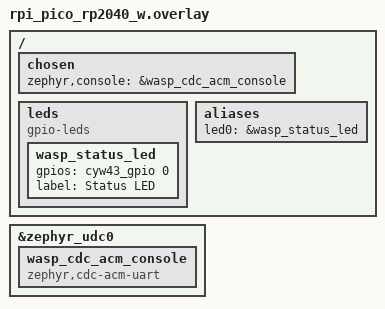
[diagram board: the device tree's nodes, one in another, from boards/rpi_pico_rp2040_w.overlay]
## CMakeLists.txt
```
cmake_minimum_required(VERSION 3.20.0)

# WAMR's zephyr module declares cmake-ext/kconfig-ext but ships no glue;
# supply it from app/modules/wamr (must be set before find_package(Zephyr)).
set(ZEPHYR_WASM_MICRO_RUNTIME_CMAKE_DIR ${CMAKE_CURRENT_SOURCE_DIR}/modules/wamr)
set(ZEPHYR_WASM_MICRO_RUNTIME_KCONFIG ${CMAKE_CURRENT_SOURCE_DIR}/modules/wamr/Kconfig)

# Local WiFi credentials (gitignored; copy wifi_credentials.conf.example).
# Merged automatically so build commands stay the same on every board.
if(EXISTS ${CMAKE_CURRENT_SOURCE_DIR}/wifi_credentials.conf)
  list(APPEND EXTRA_CONF_FILE ${CMAKE_CURRENT_SOURCE_DIR}/wifi_credentials.conf)
endif()

# Out-of-tree board definitions live at the repo root: boards/wasp/wasp_node.
# Both roots have to be set before find_package(Zephyr); DTS_ROOT is what
# makes dts/bindings/vendor-prefixes.txt visible so "wasp,..." compatibles
# are not flagged as an unknown vendor.
list(APPEND BOARD_ROOT ${CMAKE_CURRENT_SOURCE_DIR}/..)
list(APPEND DTS_ROOT ${CMAKE_CURRENT_SOURCE_DIR}/..)

find_package(Zephyr REQUIRED HINTS $ENV{ZEPHYR_BASE})
project(wasp LANGUAGES C)

target_sources(app PRIVATE
  src/main.c
  src/led.c
  src/net/netup.c
  # ROM USB bootloader entry; compiles to a pair of stubs where the SoC
  # has none.
  src/boot_dfu.c
  # Self-guards on the eth_switch devicetree node, so it compiles to nothing
  # on boards without a KSZ8794 (the Nucleos, the Picos).
  src/net/ksz8794.c
  # Likewise guards on the psram node.
  src/mem/psram.c
)

# Worker role: WAMR runtime, agent/executor threads, listening socket.
if(CONFIG_WASP_WORKER)
  target_sources(app PRIVATE
    src/rpc.c
    src/net/net_thread.c
    src/net/announce.c
    src/agent/agent_thread.c
    src/wamr/wamr_runtime.c
    src/wamr/native_remote.c
  )
endif()

target_include_directories(app PRIVATE src)

# Peer (job-owner) role: the libwasp core compiled into the firmware.
if(CONFIG_WASP_PEER)
  target_sources(app PRIVATE
    ../libwasp/src/core.c
    ../libwasp/src/host.c
    ../libwasp/src/discover.c
    ../libwasp/src/port_zephyr.c
    src/peer/peer_api.c
  )
  target_include_directories(app PRIVATE ../libwasp/include ../libwasp/src)
  # MCU-sized tables: 8 regions (~0.6 KiB), a 128-entry event queue
  # (16 B each — the conductor tracks tile provenance through it), and
  # in-flight async calls bounded by what a node can actually run at
  # once (one per instance), since each slot costs ~24 B per node.
  target_compile_definitions(app PRIVATE WASP_MAX_REGIONS=8 WASP_EVQ_CAP=128
                             WASP_MAX_INFLIGHT=4)
endif()

if(CONFIG_WASP_PEER_SMOKE)
  if(NOT EXISTS ${CMAKE_CURRENT_SOURCE_DIR}/../tools/remote_module.wasm)
    message(FATAL_ERROR "WASP_PEER_SMOKE needs tools/remote_module.wasm — run tools/build_test_module.sh")
  endif()
  target_sources(app PRIVATE src/peer/peer_smoke.c)
  generate_inc_file_for_target(app
    ${CMAKE_CURRENT_SOURCE_DIR}/../tools/remote_module.wasm
    ${ZEPHYR_BINARY_DIR}/include/generated/remote_module.wasm.inc)
endif()

if(CONFIG_WASP_CONDUCTOR)
  if(NOT EXISTS ${CMAKE_CURRENT_SOURCE_DIR}/../tools/mandelbrot_module.wasm)
    message(FATAL_ERROR "WASP_CONDUCTOR needs tools/mandelbrot_module.wasm — run tools/build_test_module.sh")
  endif()
  target_sources(app PRIVATE src/peer/conductor.c)
  generate_inc_file_for_target(app
    ${CMAKE_CURRENT_SOURCE_DIR}/../tools/mandelbrot_module.wasm
    ${ZEPHYR_BINARY_DIR}/include/generated/mandelbrot_module.wasm.inc)
endif()
```

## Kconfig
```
menu "wasp"

config WASP_WORKER
	bool "Worker role: accept a coordinator and execute WASM modules"
	default y
	help
	  The classic wasp node: WAMR runtime, agent + executor threads,
	  the listening TCP socket, and ANNOUNCE broadcasts. Disable for
	  a conductor-only build that spends its RAM on coordinating
	  other nodes instead of running modules (also set CONFIG_WAMR=n
	  there to drop the runtime).

config WASP_AGENT_PORT
	int "TCP port the agent listens on"
	default 4242

config WASP_MAX_INSTANCES
	int "Module instances a node will host at once"
	default 3
	range 1 16
	help
	  Upper bound on the module and instance tables, and therefore on the
	  executor pool and the remote-memory RPC slots — one thread and one
	  RPC slot per instance, so that an instance parked on a round trip
	  does not hold up the others.

	  This is a ceiling, not a reservation: instances are only created on
	  demand and an INSTANTIATE that the WAMR pool cannot fit answers
	  ERROR(NO_SLOTS). What it does reserve is one executor stack each
	  (WASP_EXEC_THREAD_STACK_SIZE), which comes out of the same RAM the
	  pool would otherwise fill, so raising it past what the pool can
	  back costs memory and buys nothing. A 64 KiB linear-memory page per
	  instance means roughly three fit on 320 KB of SRAM and one on
	  192 KB.

config WASP_WAMR_POOL_FILL_RAM
	bool "Give WAMR all the RAM left over after static allocation"
	default y
	help
	  Sizes the WAMR pool at boot to the span between _image_ram_end and
	  __kernel_ram_end — everything left once data, bss, noinit, the
	  thread stacks and the kernel heap have been placed.

	  This is what lets one firmware image suit boards with different
	  amounts of RAM without a per-board constant: the H723's 320 KB
	  yields about three concurrent module instances and the F439's
	  192 KB about one, from the same build. It beats a hand-tuned
	  constant on both, since a figure safe for the smallest board
	  strands RAM on every larger one.

	  Turn it off to go back to a fixed static array of
	  WASP_WAMR_HEAP_POOL_SIZE bytes.

config WASP_WAMR_HEAP_POOL_SIZE
	int "WAMR pool floor (bytes), or its exact size if not filling RAM"
	default 90112
	help
	  All WASM module memory (module structures, linear memory, exec
	  stacks) is allocated from this pool. A standard clang-built module
	  needs one contiguous 64 KiB WASM page for linear memory plus
	  runtime overhead, so this must comfortably exceed 64 KiB.

	  With WASP_WAMR_POOL_FILL_RAM set (the default) this is a floor
	  rather than the size: the pool takes all spare RAM, and init fails
	  loudly if that turns out to be less than this. Without it, this is
	  the exact size of a static array.

config WASP_MAX_MODULE_SIZE
	int "Maximum accepted .wasm module size (bytes)"
	default 32768

config WASP_WASM_STACK_SIZE
	int "WASM execution stack size (bytes, from the WAMR pool)"
	default 4096

config WASP_WASM_HEAP_SIZE
	int "Per-module-instance app heap size (bytes)"
	default 4096
	help
	  Backs malloc() inside the WASM module (libc-builtin). Carved from
	  the module's memory space at instantiation time.

config WASP_WIFI_SSID
	string "WiFi SSID (boards with WiFi only)"
	default ""
	help
	  Network the node joins before starting DHCP. Do NOT put real
	  credentials in committed files: create app/wifi_credentials.conf
	  (gitignored, merged automatically — see README) instead.

config WASP_WIFI_PSK
	string "WiFi passphrase (WPA2-PSK; empty = open network)"
	default ""

config WASP_RPC_TIMEOUT_MS
	int "Remote-memory RPC timeout (ms)"
	default 5000
	help
	  How long a wasp.* host function waits for the coordinator to
	  answer a MEM_READ/MEM_WRITE/LOCK/... request before giving up and
	  raising a WASM exception on the calling module.

config WASP_WIFI_POWERSAVE
	bool "Leave WiFi chip power save enabled"
	depends on WIFI
	help
	  The WiFi driver enables chip power save (PM2) by default. That
	  adds beacon-interval latency bursts to everything that crosses
	  the radio — remote-memory RPCs, and on the Pico W even status
	  LED writes (the LED hangs off the WiFi chip), which visibly
	  mangles the blink patterns. wasp nodes are usually mains/USB
	  powered, so wasp disables power save after connecting; enable
	  this only for battery-powered nodes that prefer power over
	  latency.

config WASP_STATUS_LED
	bool "Drive a status LED (needs an led0 devicetree alias)"
	default y
	help
	  Blink patterns show network state at a glance; the IDENTIFY
	  command strobes it so a specific board can be located. No-op on
	  boards without an led0 alias.

config WASP_ANNOUNCE_PORT
	int "UDP port for discovery broadcasts"
	default 4243

config WASP_ANNOUNCE_INTERVAL
	int "Seconds between ANNOUNCE broadcasts"
	default 5

config WASP_PEER
	bool "Peer (job-owner) role: coordinate work on other nodes"
	help
	  Compiles the libwasp core into the firmware so this node can
	  dial other nodes, push modules, call functions, and serve
	  remote-memory regions from its own RAM — i.e. play the
	  coordinator role toward its peers. Worker-only nodes leave
	  this off and pay nothing.

config WASP_PEER_RX_BUF
	int "Peer connection receive buffer (bytes)"
	depends on WASP_PEER
	default 2048
	help
	  Caps inbound frames on an outbound peer connection, including
	  the worker's bulk MEM_WRITEs — size it to the largest write a
	  delegated module makes (e.g. one framebuffer tile) plus 4.

config WASP_PEER_THREAD_STACK_SIZE
	int "Peer driver thread stack size"
	depends on WASP_PEER
	default 4096

config WASP_PEER_MAX_PEERS
	int "Most simultaneous outbound peer connections"
	depends on WASP_PEER
	default 8
	help
	  Sizes the peer-API handle table: one wasp_node plus one
	  WASP_PEER_RX_BUF receive buffer per slot (statically
	  allocated; unreferenced tables are garbage-collected out of
	  builds that do not use the peer API).

config WASP_PEER_SMOKE
	bool "Run the peer-role smoke test at boot"
	depends on WASP_PEER
	help
	  Boot-time self-test of the peer role: dial a worker, push the
	  embedded remote-memory test module, and verify its wasp.*
	  RPCs are served from this node's RAM. Result is logged as
	  PEER SMOKE: PASS/FAIL. Needs tools/remote_module.wasm built
	  (tools/build_test_module.sh).

config WASP_PEER_SMOKE_HOST
	string "Worker IP the smoke test dials"
	depends on WASP_PEER_SMOKE
	default "10.0.0.183"

config WASP_CONDUCTOR
	bool "Conductor demo: discover workers and render the Mandelbrot"
	select WASP_PEER
	help
	  Boot-time demo of firmware-driven orchestration: listen for
	  worker ANNOUNCE broadcasts, push the embedded Mandelbrot
	  module to every free worker, host the framebuffer and work
	  counter in this node's RAM, and print progress plus the
	  finished fractal on the serial console. Needs
	  tools/mandelbrot_module.wasm (tools/build_test_module.sh).

config WASP_CONDUCTOR_DISCOVER_S
	int "Seconds to listen for worker ANNOUNCEs"
	depends on WASP_CONDUCTOR
	default 8

config WASP_CONDUCTOR_CHAOS
	bool "Kill one worker's connection mid-render (resilience demo)"
	depends on WASP_CONDUCTOR
	help
	  Once a quarter of the tiles are done, the conductor drops its
	  connection to the last worker, then re-issues that worker's
	  lost tiles to the survivors at the end — the firmware version
	  of the Python demo's --chaos flag.

config WASP_PSRAM
	bool
	default y
	depends on DT_HAS_WASP_VTI7064_PSRAM_ENABLED
	select USE_STM32_HAL_OSPI
	select PINCTRL
	help
	  Hidden. Pulls in the OSPI HAL and pinctrl for app/src/mem/psram.c
	  whenever a board's devicetree has the PSRAM node enabled.

config WASP_PSRAM_ALLOW
	bool "Offer the external PSRAM for allocation"
	depends on WASP_PSRAM
	help
	  Off, and it should stay off on v1 hardware. Bulk memory-mapped
	  writes corrupt roughly one word per 352 bytes there, for reasons
	  set out at the top of app/src/mem/psram.c — an OCTOSPI AXI
	  byte-enable limitation on quad SDR parts that no driver setting
	  fixes. With this off, wasp_psram_ready() returns false and nothing
	  allocates from the window, though the driver still maps it and
	  verifies reads at boot.

	  V2 hardware moves to an octal PSRAM, which is the configuration
	  that works; this option is what turns it on there.

config WASP_PSRAM_SELFTEST
	bool "Sweep the external PSRAM at boot"
	depends on WASP_PSRAM
	help
	  Writes and verifies the whole array three times over: once with
	  each word holding its own address, once with 0x55/0xAA, and once
	  through byte and halfword accesses. Costs a second or two of boot
	  time and reports throughput. Off by default because on v1 hardware
	  it fails by design — see CONFIG_WASP_PSRAM_ALLOW.

	  The full sweep is the point. The mapped window is cacheable and the
	  H7's D-cache is on, so a short test would be served from cache and
	  would pass against a dead device.

config WASP_KSZ8794_STORM_PROTECT
	bool "Enable broadcast storm protection on the switch's external ports"
	default y
	help
	  Limits ingress broadcast traffic on the three external ports to the
	  KSZ8794's reset-default rate of 1% of 100BT (74 64-byte blocks per
	  50 ms). Port 4, the MCU side, is deliberately left unlimited so that
	  wasp's own broadcast ANNOUNCE discovery is never throttled.

config WASP_KSZ8794_HW_RESET
	bool "Pulse the switch's RST# at boot"
	help
	  Normally unnecessary: R6/C32 hold RST# low for roughly 100 ms at
	  power-on, well past the 10 ms the data sheet requires, and every
	  register this firmware writes is idempotent on a warm restart.

	  Dangerous once the clock tree is moved to HSE, because HSE is fed
	  from the switch's REFCLKO: holding the switch in reset then stops
	  the clock the CPU is running from. Only enable while on HSI.

config WASP_NET_THREAD_STACK_SIZE
	int "Network handler thread stack size"
	default 4096

config WASP_AGENT_THREAD_STACK_SIZE
	int "Agent thread stack size"
	default 4096

config WASP_EXEC_THREAD_STACK_SIZE
	int "WASM executor thread stack size"
	default 8192

endmenu

source "Kconfig.zephyr"
```

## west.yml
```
# West manifest for the wasp workspace.
#
# The repo root is the west topdir; everything external is cloned under
# deps/ (gitignored). Dependencies are pinned to release tags for
# reproducible builds — bump deliberately.
manifest:
  remotes:
    - name: zephyrproject-rtos
      url-base: https://github.com/zephyrproject-rtos
    - name: bytecodealliance
      url-base: https://github.com/bytecodealliance

  projects:
    - name: zephyr
      remote: zephyrproject-rtos
      revision: v4.4.1
      clone-depth: 1
      import:
        path-prefix: deps
        # Only pull the Zephyr modules we actually need. Add the vendor HAL
        # here when porting wasp to a new MCU family.
        name-allowlist:
          - cmsis
          - cmsis_6
          - hal_stm32
          - hal_rpi_pico  # RP2040 (Raspberry Pi Pico W)
          - hal_infineon  # CYW43439 WiFi on the Pico W

    - name: wasm-micro-runtime
      remote: bytecodealliance
      revision: WAMR-2.4.5
      clone-depth: 1
      path: deps/modules/lib/wasm-micro-runtime
```

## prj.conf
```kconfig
# Board-agnostic configuration. Per-board tuning goes in boards/<board>.conf.

# --- WASM runtime ---
CONFIG_WAMR=y

# --- logging ---
CONFIG_LOG=y

# --- networking ---
CONFIG_NETWORKING=y
CONFIG_NET_IPV4=y
CONFIG_NET_IPV6=n
CONFIG_NET_TCP=y
CONFIG_NET_SOCKETS=y
CONFIG_NET_DHCPV4=y
CONFIG_NET_MGMT=y
CONFIG_NET_MGMT_EVENT=y
CONFIG_NET_MGMT_EVENT_INFO=y
# SO_RCVTIMEO/SO_SNDTIMEO support (drop peers that stall mid-frame)
CONFIG_NET_CONTEXT_RCVTIMEO=y
CONFIG_NET_CONTEXT_SNDTIMEO=y

# --- kernel ---
CONFIG_REBOOT=y
CONFIG_MAIN_STACK_SIZE=2048
CONFIG_SYSTEM_WORKQUEUE_STACK_SIZE=2048
```

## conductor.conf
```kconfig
# Conductor-only build: no worker role, no WAMR — this node's RAM goes
# to the framebuffer and the peer connections instead, and its job is
# to discover workers and conduct the Mandelbrot render (see
# src/peer/conductor.c). Build with:
#   west build -b nucleo_f439zi app -d build/conductor -- -DEXTRA_CONF_FILE=conductor.conf
CONFIG_WASP_WORKER=n
CONFIG_WAMR=n
CONFIG_WASP_CONDUCTOR=y

# Room for one UDP discovery socket + up to 8 outbound TCP connections
# (the worker build only ever holds 4 fds; defaults are sized for it).
CONFIG_ZVFS_OPEN_MAX=12
CONFIG_NET_MAX_CONN=12
CONFIG_NET_MAX_CONTEXTS=12
# Zephyr's default ARP table holds TWO entries — with five workers on
# the subnet it thrashes, TX responses stall behind re-resolution, and
# all but ~2 connections starve into RPC timeouts (observed).
CONFIG_NET_ARP_TABLE_SIZE=16

# Five workers stream 524 B tile writes concurrently. With the default
# pools the RX path collapses: in-order data parked in socket receive
# queues between conductor polls eats the pool, inbound ACKs start
# dropping, and every stream degenerates into retransmission backoff
# (observed: total stall until a connection died and freed its share).
# Big RX pool + a per-connection window cap so N conns cannot
# overcommit it: 8 x 1536 B windows = 12 KiB < 16 KiB of RX bufs.
CONFIG_NET_PKT_RX_COUNT=64
CONFIG_NET_PKT_TX_COUNT=32
CONFIG_NET_BUF_RX_COUNT=128
CONFIG_NET_BUF_TX_COUNT=64
CONFIG_NET_TCP_MAX_RECV_WINDOW_SIZE=1536

# The render-loop progress logs come in bursts; don't drop them.
CONFIG_LOG_BUFFER_SIZE=8192
```

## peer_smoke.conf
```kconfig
# Peer-role smoke build: this node boots, dials the worker below, and
# coordinates it (see src/peer/peer_smoke.c). Build with:
#   west build -b nucleo_f439zi app -d build/peer -- -DEXTRA_CONF_FILE=peer_smoke.conf
CONFIG_WASP_PEER=y
CONFIG_WASP_PEER_SMOKE=y
CONFIG_WASP_PEER_SMOKE_HOST="10.0.0.183"
```

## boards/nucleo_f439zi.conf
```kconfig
# ST Nucleo-F439ZI (Cortex-M4F, 192K SRAM + 64K CCM, on-board LAN8742 PHY).
# Per-board tuning only — keep anything board-agnostic in prj.conf.

# One instance. A 64 KiB linear-memory page plus stacks and heap is most of
# this board's RAM, so the pool can only ever back one — and each unusable
# slot would still reserve an executor stack, taking RAM from the pool that
# the one real instance wants.
CONFIG_WASP_MAX_INSTANCES=1
```

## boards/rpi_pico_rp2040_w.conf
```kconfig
# Raspberry Pi Pico W (RP2040 Cortex-M0+ @ 133 MHz, 264 KiB SRAM, 2 MB
# flash, CYW43439 WiFi). Per-board tuning only — keep anything
# board-agnostic in prj.conf.

# WiFi — CYW43439 via the Infineon AIROC driver (defaults on once WIFI
# is enabled; firmware blobs required once: `west blobs fetch hal_infineon`).
# Credentials come from the gitignored app/wifi_credentials.conf.
CONFIG_WIFI=y

# RP2040 has no hardware TRNG. Pseudo-random suffices for a LAN test
# node (TCP sequence numbers, DHCP ids — nothing cryptographic).
CONFIG_TEST_RANDOM_GENERATOR=y

# Console on USB CDC ACM — the Pico W has no on-board UART-to-USB bridge
# (same configuration as the upstream cdc-acm-console snippet).
CONFIG_USB_DEVICE_STACK_NEXT=y
CONFIG_CDC_ACM_SERIAL_INITIALIZE_AT_BOOT=y
CONFIG_UART_LINE_CTRL=y

# One instance. A 64 KiB linear-memory page plus stacks and heap is most of
# this board's RAM, so the pool can only ever back one — and each unusable
# slot would still reserve an executor stack, taking RAM from the pool that
# the one real instance wants.
CONFIG_WASP_MAX_INSTANCES=1
```

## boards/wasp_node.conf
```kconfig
# wasp node board, rev V1 — STM32H723ZGT6, 320 KB AXI SRAM + 128 KB DTCM,
# KSZ8794CNX switch on SPI3, quad PSRAM on OCTOSPI1 (not yet enabled).
# Per-board tuning only — keep anything board-agnostic in prj.conf.
#
# Deliberately almost empty for the first bring-up: the F439 and Pico configs
# were grown against observed failures, and guessing at tuning before the
# board has ever booted just produces failures that are hard to attribute.
#
# Known to be worth revisiting once it boots:
#   - WASP_WAMR_HEAP_POOL_SIZE: 88 KiB is sized for the F439's 192 KB SRAM.
#     This board has 320 KB of AXI SRAM, so the pool can grow a lot, which
#     means bigger or more concurrent WASM modules.
#   - NET_ARP_TABLE_SIZE: defaults to 2. Every node on this board is behind
#     its own 3-port switch, so a node talks to more peers than on the
#     F439 bench — the conductor work already showed table thrashing at
#     5 peers starving TCP into RPC timeouts. See conductor.conf.
```

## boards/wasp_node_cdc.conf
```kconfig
# Opt-in: move the console from USART3 (J9.3/J9.4) to the board's own USB-C.
#
#   west build -b wasp_node app -- \
#       -DEXTRA_CONF_FILE=boards/wasp_node_cdc.conf \
#       -DEXTRA_DTC_OVERLAY_FILE=boards/wasp_node_cdc.overlay
#
# The tradeoff: no USB-TTL dongle needed, but nothing prints until the host
# enumerates the device, so a hang in clock or driver init is invisible. That
# is why USART3 is the default while the board is still unproven.

CONFIG_USB_DEVICE_STACK=y
CONFIG_USB_DEVICE_PRODUCT="wasp node"
CONFIG_USB_DEVICE_MANUFACTURER="wasp"
CONFIG_USB_CDC_ACM=y
CONFIG_USB_DEVICE_INITIALIZE_AT_BOOT=y
CONFIG_UART_LINE_CTRL=y
```

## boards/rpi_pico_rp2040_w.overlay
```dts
/* Console on USB CDC ACM — the Pico W exposes no UART over its USB port. */
/ {
	chosen {
		zephyr,console = &wasp_cdc_acm_console;
	};

	/* The board DTS defines no LED: the Pico W LED sits on the CYW43439
	 * WiFi chip (WL_GPIO0), reached through the cyw43_gpio controller. */
	leds {
		compatible = "gpio-leds";
		wasp_status_led: wasp_status_led {
			gpios = <&cyw43_gpio 0 GPIO_ACTIVE_HIGH>;
			label = "Status LED";
		};
	};

	aliases {
		led0 = &wasp_status_led;
	};
};

&zephyr_udc0 {
	wasp_cdc_acm_console: wasp_cdc_acm_console {
		compatible = "zephyr,cdc-acm-uart";
	};
};
```

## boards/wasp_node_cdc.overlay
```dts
/*
 * Console over USB-C CDC-ACM instead of USART3. Pairs with
 * boards/wasp_node_cdc.conf — see that file for the invocation.
 */

&zephyr_udc0 {
	cdc_acm_uart0: cdc-acm-uart0 {
		compatible = "zephyr,cdc-acm-uart";
	};
};

/ {
	chosen {
		zephyr,console = &cdc_acm_uart0;
		zephyr,shell-uart = &cdc_acm_uart0;
	};
};
```

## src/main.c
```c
/*
 * wasp — WebAssembly Swarm Processor node.
 *
 * main() only owns the shared plumbing (queues, payload heap, tx helpers)
 * and a boot banner; the worker threads are defined in their own modules
 * and start via K_THREAD_DEFINE.
 */
#include <string.h>

#include <zephyr/devicetree.h>
#include <zephyr/init.h>
#include <zephyr/kernel.h>
#include <zephyr/linker/section_tags.h>
#include <zephyr/logging/log.h>

#include "wasp.h"

LOG_MODULE_REGISTER(wasp, LOG_LEVEL_INF);

#ifdef CONFIG_WASP_WORKER

#define WASP_QUEUE_DEPTH 8

/*
 * Payload buffers travel through the queues by pointer; this heap backs
 * them. Sized to hold one max-size module (which stays allocated while
 * loaded) plus working room for control traffic.
 *
 * Placed in tightly-coupled memory when the board has it (CPU-only access
 * is fine — payloads are only ever memcpy'd). The WAMR pool deliberately
 * does NOT live in DTCM: it must satisfy a contiguous 64 KiB+ allocation
 * for a module's linear memory (one WASM page), which a 64 KiB TCM can
 * never fit alongside the runtime's own allocations, so it lives in main
 * SRAM and this heap takes the TCM instead.
 */
#define WASP_PAYLOAD_HEAP_SIZE (CONFIG_WASP_MAX_MODULE_SIZE + 8192)
#if DT_HAS_CHOSEN(zephyr_dtcm)
static uint8_t payload_heap_buf[WASP_PAYLOAD_HEAP_SIZE] __dtcm_noinit_section;
#else
static uint8_t payload_heap_buf[WASP_PAYLOAD_HEAP_SIZE] __noinit;
#endif
struct k_heap wasp_payload_heap;

static int wasp_payload_heap_init(void)
{
	k_heap_init(&wasp_payload_heap, payload_heap_buf, sizeof(payload_heap_buf));
	return 0;
}
/* POST_KERNEL: before the K_THREAD_DEFINE'd worker threads start. */
SYS_INIT(wasp_payload_heap_init, POST_KERNEL, 0);

K_MSGQ_DEFINE(wasp_rx_q, sizeof(struct wasp_msg), WASP_QUEUE_DEPTH, 4);
K_MSGQ_DEFINE(wasp_tx_q, sizeof(struct wasp_msg), WASP_QUEUE_DEPTH, 4);
K_MSGQ_DEFINE(wasp_exec_q, sizeof(struct wasp_msg), WASP_QUEUE_DEPTH, 4);

int wasp_queue_tx(const struct wasp_msg *req, uint8_t type, const void *payload, uint32_t len)
{
	struct wasp_msg msg = {
		.type = type,
		.seq = req->seq,
		.conn = req->conn,
		.len = len,
	};

	if (len > 0) {
		msg.payload = k_heap_alloc(&wasp_payload_heap, len, K_MSEC(100));
		if (msg.payload == NULL) {
			LOG_ERR("no memory for %u byte response, dropping", len);
			return -ENOMEM;
		}
		memcpy(msg.payload, payload, len);
	}

	if (k_msgq_put(&wasp_tx_q, &msg, K_MSEC(100)) != 0) {
		LOG_ERR("tx queue full, dropping response type 0x%02x", type);
		if (msg.payload != NULL) {
			k_heap_free(&wasp_payload_heap, msg.payload);
		}
		return -EAGAIN;
	}
	return 0;
}

int wasp_queue_error(const struct wasp_msg *req, uint8_t err, const char *detail)
{
	uint8_t buf[1 + 96];
	uint32_t len = 1;

	buf[0] = err;
	if (detail != NULL) {
		len += strlen(detail);
		len = MIN(len, sizeof(buf));
		memcpy(&buf[1], detail, len - 1);
	}
	return wasp_queue_tx(req, WASP_MSG_ERROR, buf, len);
}

#endif /* CONFIG_WASP_WORKER */

/*
 * Report the clock tree the SoC actually ended up with, not the one the
 * devicetree asked for. On the wasp node board these differ in an
 * interesting way: HSE is bypass-fed from the Ethernet switch's REFCLKO,
 * so "did the PLL lock onto a real 25 MHz?" is a board-level question,
 * and the answer is otherwise invisible — a silent fallback and a correct
 * boot look identical from the console.
 */
#if defined(CONFIG_SOC_SERIES_STM32H7X)
#include <stm32_ll_rcc.h>

static void log_clock_tree(void)
{
	static const char *const src[] = { "HSI", "CSI", "HSE", "PLL1" };
	uint32_t sws = LL_RCC_GetSysClkSource() >> RCC_CFGR_SWS_Pos;

	LOG_INF("sysclk %u MHz from %s (HSE %s, PLL1 %s), HCLK %u MHz",
		HAL_RCC_GetSysClockFreq() / 1000000U,
		src[sws & 0x3],
		LL_RCC_HSE_IsReady() ? "ready" : "off",
		LL_RCC_PLL1_IsReady() ? "locked" : "off",
		HAL_RCC_GetHCLKFreq() / 1000000U);
}
#elif defined(CONFIG_SOC_FAMILY_STM32)
static void log_clock_tree(void)
{
	/* The per-series LL names for the PLL and HSE ready flags differ
	 * (LL_RCC_PLL_IsReady on F4 against LL_RCC_PLL1_IsReady on H7), and
	 * the detail above only earns its keep on a board whose HSE comes
	 * from another chip on the PCB. Elsewhere the rates are enough.
	 */
	LOG_INF("sysclk %u MHz, HCLK %u MHz",
		HAL_RCC_GetSysClockFreq() / 1000000U,
		HAL_RCC_GetHCLKFreq() / 1000000U);
}
#else
static void log_clock_tree(void) { }
#endif

int main(void)
{
	LOG_INF("wasp node booting (board: %s)", CONFIG_BOARD);
	log_clock_tree();
	return 0;
}
```

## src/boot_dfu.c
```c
/*
 * Entry into the SoC's ROM USB bootloader, for reflashing without a
 * debugger.
 *
 * Copyright (c) 2026 Oskar von Heideken
 * SPDX-License-Identifier: Apache-2.0
 *
 * The STM32H7 carries a DFU-capable bootloader in system memory. Holding
 * SW2 (BOOT0 high, against R27's 10k pull-down) through a reset runs it
 * with no help from us at all. This file is the other way in: a
 * coordinator can ask for it over the network, the way an RP2040 node is
 * already asked for BOOTSEL, so a board on a shelf can be reflashed
 * without anybody reaching for the button.
 *
 * Jumping straight there from a running system is the obvious
 * implementation and the wrong one. By the time a request arrives this
 * MCU is at 550 MHz on a PLL fed from the Ethernet switch, with both
 * caches on, Ethernet DMA running and interrupts live; the ROM
 * bootloader expects none of that, and tearing it all down by hand is a
 * long list of things to get right once and then quietly break.
 *
 * So instead: leave a magic word in uninitialised RAM, reset, and jump
 * before anything has been set up. NVIC_SystemReset does not clear SRAM
 * and __noinit is not zeroed by the C startup, so the word survives the
 * reset that discards all the state we would otherwise have had to undo.
 * At PRE_KERNEL_1 priority 0 the clock driver (priority 1) has not run,
 * so the chip is still on its reset defaults — which is exactly the
 * state the ROM bootloader was written for.
 *
 * The address is not taken on trust. 0x1FF09800 is widely reported for
 * the H7, but reports are mostly from H743 silicon, so the vector is
 * read and sanity-checked first: a stack pointer somewhere in RAM and a
 * Thumb entry point inside system memory. Read over SWD on this board it
 * is SP=0x24003f40, PC=0x1ff1393d, which passes. If some future part
 * disagrees, the check fails and the node boots normally instead of
 * hanging somewhere unreachable.
 */
#include <zephyr/init.h>
#include <zephyr/kernel.h>
#include <zephyr/linker/section_tags.h>
#include <zephyr/logging/log.h>
#include <zephyr/sys/reboot.h>

#include "wasp.h"

LOG_MODULE_REGISTER(wasp_dfu, LOG_LEVEL_INF);

#if defined(CONFIG_SOC_SERIES_STM32H7X)

#include <cmsis_core.h>

/* System memory vector table. Verified by reading it on the target. */
#define BOOTLOADER_VECTORS 0x1FF09800UL
#define SYSMEM_BASE        0x1FF00000UL
#define SYSMEM_END         0x1FF20000UL

/* Any even, unlikely value; it only has to not occur by accident in RAM
 * that nothing initialises.
 */
#define DFU_MAGIC 0xB0075EL

static uint32_t dfu_request __noinit;

/*
 * Diagnostics, surviving the reset alongside the request so the outcome
 * of an attempt can be reported once logging is up. Two distinct tags,
 * because "the vector looked wrong" and "we jumped and ended up back
 * here" are very different failures and the first version of this could
 * not tell them apart.
 */
static uint32_t dfu_dbg_tag __noinit;
static uint32_t dfu_dbg_sp __noinit;
static uint32_t dfu_dbg_pc __noinit;
#define DFU_DBG_REJECTED 0x5A5AA5A5UL
#define DFU_DBG_JUMPED   0x1234BEEFUL

bool wasp_boot_dfu_supported(void)
{
	return true;
}

void wasp_boot_dfu(void)
{
	dfu_request = DFU_MAGIC;
	sys_reboot(SYS_REBOOT_COLD);
}

static int dfu_entry(void)
{
	uint32_t sp, pc;

	if (dfu_request != DFU_MAGIC) {
		return 0;
	}
	/* Clear first: if the jump below is wrong, the next reset must boot
	 * the application rather than retry forever.
	 */
	dfu_request = 0;

	sp = *(volatile uint32_t *)BOOTLOADER_VECTORS;
	pc = *(volatile uint32_t *)(BOOTLOADER_VECTORS + 4);
	dfu_dbg_sp = sp;
	dfu_dbg_pc = pc;

	/* A plausible Cortex-M vector: stack in RAM, Thumb entry inside
	 * system memory. Anything else and we carry on booting.
	 */
	if (sp < CONFIG_SRAM_BASE_ADDRESS ||
	    sp > CONFIG_SRAM_BASE_ADDRESS + KB(CONFIG_SRAM_SIZE) ||
	    pc < SYSMEM_BASE || pc >= SYSMEM_END || (pc & 1U) == 0U) {
		dfu_dbg_tag = DFU_DBG_REJECTED;
		return 0;
	}

	/* Past the check, so any later appearance of this tag means the
	 * bootloader handed control back rather than staying resident.
	 */
	dfu_dbg_tag = DFU_DBG_JUMPED;

	__disable_irq();

	/* Caches are enabled before PRE_KERNEL_1. Clean the data cache
	 * rather than merely disabling it, or dirty lines are dropped.
	 */
	SCB_CleanInvalidateDCache();
	SCB_DisableDCache();
	SCB_DisableICache();

	/* Nothing has been configured yet, but the reset defaults still
	 * leave SysTick and any latched NVIC state to clear.
	 */
	SysTick->CTRL = 0;
	SysTick->LOAD = 0;
	SysTick->VAL = 0;
	for (unsigned int i = 0; i < ARRAY_SIZE(NVIC->ICER); i++) {
		NVIC->ICER[i] = 0xFFFFFFFFU;
		NVIC->ICPR[i] = 0xFFFFFFFFU;
	}

	SCB->VTOR = BOOTLOADER_VECTORS;
	__DSB();
	__ISB();
	__set_MSP(sp);
	((void (*)(void))pc)();

	CODE_UNREACHABLE;
}

/* Report what the last attempt saw, if there was one. */
static int dfu_report(void)
{
	uint32_t tag = dfu_dbg_tag;

	/* Clear whatever is there, not just a value we recognise: these
	 * live in uninitialised RAM and survive a reflash, so a tag left by
	 * a previous firmware would otherwise be reported on every boot.
	 */
	dfu_dbg_tag = 0;

	if (tag == DFU_DBG_REJECTED) {
		LOG_WRN("DFU: vector at 0x%08x failed its sanity check "
			"(SP=0x%08x PC=0x%08x) — booted normally instead",
			(unsigned int)BOOTLOADER_VECTORS, dfu_dbg_sp, dfu_dbg_pc);
	} else if (tag == DFU_DBG_JUMPED) {
		/*
		 * The jump ran and the ROM bootloader gave control back. Per
		 * AN2606 the H7 bootloader samples its interfaces and leaves
		 * for the application when it finds no host, so the usual
		 * cause is the board's USB-C not being a data link to a PC —
		 * a charger or a power-only cable looks the same to it.
		 */
		LOG_WRN("DFU: jumped to the ROM bootloader and it returned. "
			"It leaves for the application when no USB host "
			"answers — check USB-C (J7) is a data cable to a PC.");
	}
	return 0;
}
SYS_INIT(dfu_report, POST_KERNEL, 4);

/*
 * PRE_KERNEL_1 priority 0: ahead of the clock driver at priority 1, so
 * the PLLs are still off and the chip is on its reset-default HSI. That
 * ordering is the whole design — see the file comment.
 */
SYS_INIT(dfu_entry, PRE_KERNEL_1, 0);

#else

bool wasp_boot_dfu_supported(void)
{
	return false;
}

void wasp_boot_dfu(void)
{
}

#endif /* CONFIG_SOC_SERIES_STM32H7X */
```

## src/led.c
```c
/*
 * Status LED driver thread (see led.h for the patterns).
 *
 * A dedicated thread rather than a k_timer because setting the pin may
 * block: on the Pico W the LED hangs off the CYW43439 WiFi chip and a
 * write is a WHD ioctl over SPI — nothing an ISR may touch.
 */
#include <zephyr/kernel.h>

#include "led.h"

#if DT_NODE_EXISTS(DT_ALIAS(led0)) && defined(CONFIG_WASP_STATUS_LED)

#include <zephyr/drivers/gpio.h>
#include <zephyr/logging/log.h>

LOG_MODULE_REGISTER(wasp_led, LOG_LEVEL_INF);

static const struct gpio_dt_spec led = GPIO_DT_SPEC_GET(DT_ALIAS(led0), gpios);

static atomic_t led_state = ATOMIC_INIT(WASP_LED_NET_DOWN);
static atomic_t identify_until; /* k_uptime_get_32() deadline, 0 = inactive */

void wasp_led_set(enum wasp_led_state state)
{
	atomic_set(&led_state, state);
}

void wasp_led_identify(uint32_t duration_ms)
{
	atomic_set(&identify_until, (atomic_val_t)(k_uptime_get_32() + duration_ms));
}

/* Set the pin and report the tick's sleep time. Split into on-time and
 * off-time per period so state changes are picked up quickly. */
static void led_thread_fn(void *a, void *b, void *c)
{
	ARG_UNUSED(a);
	ARG_UNUSED(b);
	ARG_UNUSED(c);

	/* The CYW43 GPIO controller is only usable once the WiFi driver
	 * has initialized; be patient rather than sorry. */
	while (!gpio_is_ready_dt(&led)) {
		k_sleep(K_MSEC(100));
	}
	if (gpio_pin_configure_dt(&led, GPIO_OUTPUT_INACTIVE) != 0) {
		LOG_WRN("cannot configure status LED, giving up");
		return;
	}
	LOG_INF("status LED on %s pin %u", led.port->name, led.pin);

	bool on = false;

	while (true) {
		uint32_t now = k_uptime_get_32();
		int32_t sleep_ms;

		if ((int32_t)(atomic_get(&identify_until) - now) > 0) {
			on = !on; /* 10 Hz strobe: unmissable */
			sleep_ms = 50;
		} else {
			switch (atomic_get(&led_state)) {
			case WASP_LED_NET_DOWN:
				on = !on;
				sleep_ms = 100;
				break;
			case WASP_LED_CONNECTED:
				on = true;
				sleep_ms = 200;
				break;
			case WASP_LED_READY:
			default:
				on = !on;
				sleep_ms = on ? 80 : 920;
				break;
			}
		}
		(void)gpio_pin_set_dt(&led, on);
		k_sleep(K_MSEC(sleep_ms));
	}
}

/* 2 KiB stack: a pin write on the Pico W goes through the WHD driver. */
K_THREAD_DEFINE(wasp_led_tid, 2048, led_thread_fn, NULL, NULL, NULL, K_PRIO_PREEMPT(12), 0, 0);

#else /* no led0 alias or LED disabled */

void wasp_led_set(enum wasp_led_state state)
{
	ARG_UNUSED(state);
}

void wasp_led_identify(uint32_t duration_ms)
{
	ARG_UNUSED(duration_ms);
}

#endif
```

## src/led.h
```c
/*
 * Status LED — one glance tells you what a node is doing:
 *
 *   fast blink (5 Hz)   no network yet (WiFi joining / DHCP)
 *   heartbeat (short blip every second)   online, waiting for a coordinator
 *   solid on            coordinator connected
 *   frantic strobe      IDENTIFY received — "here I am"
 *
 * Compiles to no-ops on boards without an led0 devicetree alias.
 */
#ifndef WASP_LED_H_
#define WASP_LED_H_

#include <stdint.h>

enum wasp_led_state {
	WASP_LED_NET_DOWN,  /* fast blink */
	WASP_LED_READY,     /* heartbeat */
	WASP_LED_CONNECTED, /* solid */
};

void wasp_led_set(enum wasp_led_state state);

/* Strobe for duration_ms so a human can spot the board, then revert. */
void wasp_led_identify(uint32_t duration_ms);

#endif /* WASP_LED_H_ */
```

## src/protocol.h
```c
/*
 * wasp wire protocol — single source of truth for the frame format.
 * Keep in sync with tools/wasp_client.py (and eventually the coordinator).
 *
 * All frames, both directions:
 *
 *   ┌───────────┬──────────┬─────────┬────────────┬───────────┐
 *   │ 'W' 'A'   │ type u8  │ seq u8  │ len u32 LE │ payload   │
 *   └───────────┴──────────┴─────────┴────────────┴───────────┘
 *
 * Responses echo the seq of the request they answer. Payload length is
 * capped at CONFIG_WASP_MAX_MODULE_SIZE (advertised in HELLO_ACK).
 *
 * Payloads:
 *   HELLO      (c->n): [proto_version u8]
 *   HELLO_ACK  (n->c): [proto_version u8][max_payload u32 LE][features u8]
 *   LOAD_MODULE(c->n): [.wasm binary]; success ack is an empty RESULT
 *   UNLOAD_MODULE (c->n): empty; success ack is an empty RESULT
 *   CALL       (c->n): [name_len u8][name][argc u8][arg u32 LE × argc]
 *                      v1 calling convention: i32 args/results only
 *
 * The three above address "the" module, of which there is one. They are
 * kept exactly as they were and are now sugar for the default instance,
 * so every existing client keeps working untouched. Nodes that can host
 * more than one module advertise WASP_FEAT_MULTI_INSTANCE and also accept:
 *
 *   MODULE_UPLOAD (c->n): [n_inst u8][.wasm binary]
 *                 (n->c): RESULT [mod u8][n u8][inst u8 × n]
 *   INSTANTIATE   (c->n): [mod u8][count u8]
 *                 (n->c): RESULT [count u8][inst u8 × count]
 *   CALL_INST     (c->n): [inst u8][name_len u8][name][argc u8][arg u32 × argc]
 *                 (n->c): RESULT, as CALL
 *   DROP          (c->n): [kind u8][handle u8]
 *                         kind 0 = instance, 1 = module (and its instances)
 *                 (n->c): RESULT, empty
 *   STATS         (c->n): [reset u8: non-zero clears the counters after
 *                         reporting]
 *                 (n->c): RESULT [n u8][{inst u8, calls u32, traps u32,
 *                         exec_us u32, rpc_count u32, rpc_wait_us u32,
 *                         rpc_tx u32, rpc_rx u32} x n]  (all LE)
 *
 * STATS is per instance because that is the grain the interesting
 * question has: how much of a call went into the interpreter and how much
 * into waiting for the coordinator. Instances of one node interleave
 * precisely so one computes while another waits, so a node-wide total
 * hides it. rpc_wait_us is accrued *inside* exec_us, which is what makes
 * the split arithmetic work:
 *
 *     compute  = exec_us - rpc_wait_us
 *     waiting  = rpc_wait_us / exec_us
 *
 * Microseconds, not nanoseconds, so a u32 covers ~71 minutes of
 * accumulated time per counter.
 *
 * The last row always carries inst = 0xFF: the totals of instances that
 * have since been dropped. Without it, "run a workload then ask what
 * happened" reports nothing, because the counters live on the instance
 * and releasing the module is the last thing a client does. 0xFF can
 * never name a live instance, the table being far smaller than the
 * sixteen slots a handle's index field could address.
 *
 *   INVENTORY     (c->n): empty
 *                 (n->c): RESULT [slots_total u8][slots_free u8]
 *                         [pool_free u32 LE][n_mod u8]
 *                         [{mod u8, n_inst u8, inst u8 × n_inst} × n_mod]
 *
 * The split is WAMR's own: a *module* is validated bytecode
 * (wasm_module_t), an *instance* is an instantiation of it with its own
 * linear memory (wasm_module_inst_t). Separating them is what lets the
 * same bytecode back several instances and different bytecode run side by
 * side, and it is why MODULE_UPLOAD carries a count: n_inst = 3 sends the
 * binary once and returns three instance handles in one round trip, while
 * n_inst = 0 uploads without instantiating. INSTANTIATE adds instances to
 * bytecode the node already holds, with nothing re-sent. Instances are
 * independent — nothing ties a node's instances to one program.
 *
 * Handles are (gen:4 | idx:4). The generation is not decoration: without
 * it, dropping instance 1 and instantiating into the freed slot would make
 * a stale CALL_INST execute against whatever now lives there. Reusing a
 * retired handle answers ERROR(BAD_HANDLE) instead.
 *
 * Only one call runs per instance at a time (a second concurrent CALL_INST
 * on the same instance answers ERROR(BUSY)); calls to *different*
 * instances do run concurrently, which is the point — an instance parked
 * on a remote-memory round trip is not holding up the others.
 *   RESULT     (n->c): [nresults u8][value u32 LE × nresults]
 *   ERROR      (n->c): [error code u8 (enum wasp_err)][utf8 detail, optional]
 *   PING       (c->n): arbitrary; PONG echoes it back
 *   IDENTIFY   (c->n): [duration_s u8, optional (default 10)]; strobes the
 *                      status LED so a human can find the board; ack RESULT
 *   REBOOT     (c->n): [mode u8, optional: 0=reboot (default),
 *                      1=USB bootloader (RP2040 only, for reflashing)];
 *                      acks RESULT, then reboots ~500 ms later
 *
 * Discovery: nodes broadcast an ANNOUNCE datagram to UDP port
 * CONFIG_WASP_ANNOUNCE_PORT every CONFIG_WASP_ANNOUNCE_INTERVAL seconds
 * (not wire-framed — it IS the payload, source IP identifies the node):
 *
 *   ['W']['A'][ANNOUNCE u8][version u8][features u8][tcp port u16 LE]
 *   [busy u8: coordinator currently connected][board_len u8][board name]
 *   [slots_total u8][slots_free u8][pool_free u32 LE]
 *
 * The three capacity fields come after the board name precisely so that
 * they are optional: a reader that stops at the end of the name sees the
 * v1 datagram, which is how existing clients keep working. They matter
 * because `busy` is now too coarse — a node with three slots and one in
 * use is not busy — and because the WAMR pool is sized at boot from
 * whatever RAM the board has left over, so capacity is a property of the
 * node rather than of the firmware. A coordinator can see that one node
 * has room for three instances and another for one without connecting to
 * either.
 *
 * Remote memory (feature bit WASP_FEAT_REMOTE_MEM): the 0x4x range is
 * node-initiated — sent by the node mid-CALL, answered by the
 * coordinator. These use the node's own seq space, so both directions
 * can be in flight on the one connection without ambiguity. A remote
 * reference packs (region_id:8 | offset:24) into a u32; the coordinator
 * is the authoritative bounds/lock checker. Failures are answered with
 * ERROR (c->n), echoing the node's seq.
 *
 *   MEM_READ   (n->c): [ref u32 LE][len u32 LE]
 *   MEM_DATA   (c->n): [data × len]
 *   MEM_WRITE  (n->c): [ref u32 LE][data]
 *   MEM_ACK    (c->n): empty (also acks UNLOCK)
 *   LOCK       (n->c): [region_id u8]; held-by-other -> ERROR(LOCKED),
 *                      or the coordinator may park the request and grant
 *                      when the region frees (queued locks are
 *                      coordinator policy — the node blocks on the
 *                      response either way, so it needs no opinion)
 *   LOCK_GRANT (c->n): [lease_ms u32 LE]
 *   UNLOCK     (n->c): [region_id u8]; ack is MEM_ACK
 *   REGION_INFO(n->c): [region_id u8]
 *   REGION_DESC(c->n): [length u32 LE]
 *
 * Atomic primitives (feature bit WASP_FEAT_ATOMICS): the coordinator
 * already serializes each request, so performing the whole
 * read-modify-write inside that window makes it race-free with no lock
 * and no lease — one round-trip replaces LOCK/READ/WRITE/UNLOCK. Both
 * respect a lock held by another node (ERROR(LOCKED)) and answer with
 * the OLD value:
 *
 *   MEM_ADD    (n->c): [ref u32 LE][delta i32 LE]; *ref += delta
 *   MEM_CAS    (n->c): [ref u32 LE][expected u32 LE][desired u32 LE];
 *                      writes desired only if *ref == expected — the
 *                      answered old value tells the node whether it won
 *   (both answered with MEM_DATA [old value u32 LE])
 */
#ifndef WASP_PROTOCOL_H_
#define WASP_PROTOCOL_H_

#define WASP_PROTO_MAGIC0 0x57 /* 'W' */
#define WASP_PROTO_MAGIC1 0x41 /* 'A' */
#define WASP_PROTO_VERSION 1

#define WASP_FRAME_HDR_SIZE 8
#define WASP_FRAME_OFF_MAGIC 0
#define WASP_FRAME_OFF_TYPE 2
#define WASP_FRAME_OFF_SEQ 3
#define WASP_FRAME_OFF_LEN 4

enum wasp_msg_type {
	WASP_MSG_HELLO = 0x01,
	WASP_MSG_HELLO_ACK = 0x02,
	WASP_MSG_LOAD_MODULE = 0x03,
	WASP_MSG_UNLOAD_MODULE = 0x04,
	WASP_MSG_CALL = 0x05,
	WASP_MSG_RESULT = 0x06,
	WASP_MSG_ERROR = 0x07,
	WASP_MSG_PING = 0x08,
	WASP_MSG_PONG = 0x09,
	WASP_MSG_IDENTIFY = 0x0A, /* strobe the status LED to locate the board */
	WASP_MSG_REBOOT = 0x0B,   /* reboot the node (optionally into its bootloader) */
	WASP_MSG_ANNOUNCE = 0x0C, /* UDP broadcast datagram, never on the TCP stream */

	/* Multi-instance API (WASP_FEAT_MULTI_INSTANCE). */
	WASP_MSG_MODULE_UPLOAD = 0x0D,
	WASP_MSG_INSTANTIATE = 0x0E,
	WASP_MSG_CALL_INST = 0x0F,
	WASP_MSG_DROP = 0x10,
	WASP_MSG_INVENTORY = 0x11,
	WASP_MSG_STATS = 0x12,

	/* 0x4x: node-initiated remote-memory traffic (node's seq space). */
	WASP_MSG_MEM_READ = 0x40,
	WASP_MSG_MEM_DATA = 0x41,
	WASP_MSG_MEM_WRITE = 0x42,
	WASP_MSG_MEM_ACK = 0x43,
	WASP_MSG_LOCK = 0x44,
	WASP_MSG_LOCK_GRANT = 0x45,
	WASP_MSG_UNLOCK = 0x46,
	WASP_MSG_REGION_INFO = 0x47,
	WASP_MSG_REGION_DESC = 0x48,
	WASP_MSG_MEM_ADD = 0x49,
	WASP_MSG_MEM_CAS = 0x4A,
};

/* HELLO_ACK feature bits. */
#define WASP_FEAT_REMOTE_MEM 0x01
#define WASP_FEAT_ATOMICS 0x02
#define WASP_FEAT_MULTI_INSTANCE 0x04

/* DROP kinds. */
#define WASP_DROP_INSTANCE 0
#define WASP_DROP_MODULE 1

/*
 * Module and instance handles: (gen:4 | idx:4). Four bits of index caps
 * the tables at 16, which is far above what a 64 KiB linear memory per
 * instance allows on any board this runs on, and leaves four bits of
 * generation to retire handles with.
 */
#define WASP_HANDLE_SLOTS 16
#define WASP_HANDLE(idx, gen) ((uint8_t)((((gen) & 0x0F) << 4) | ((idx) & 0x0F)))
#define WASP_HANDLE_IDX(h) ((uint8_t)((h) & 0x0F))
#define WASP_HANDLE_GEN(h) ((uint8_t)(((h) >> 4) & 0x0F))

/* Remote reference packing: (region_id:8 | offset:24). */
#define WASP_REF_REGION(ref) ((uint32_t)(ref) >> 24)
#define WASP_REF_OFFSET(ref) ((uint32_t)(ref) & 0x00FFFFFF)
#define WASP_REF_MAX_OFFSET  0x01000000

enum wasp_err {
	WASP_ERR_UNSUPPORTED = 0x01, /* valid type the node can't handle (yet) */
	WASP_ERR_BAD_TYPE = 0x02,
	WASP_ERR_TOO_LARGE = 0x03,
	WASP_ERR_NO_MEM = 0x04,
	WASP_ERR_BUSY = 0x05,
	WASP_ERR_NO_MODULE = 0x06,  /* CALL/UNLOAD with no module loaded */
	WASP_ERR_INTERNAL = 0x07,
	WASP_ERR_LOAD_FAILED = 0x08, /* module rejected by WAMR loader/instantiation */
	WASP_ERR_TRAP = 0x09,        /* module trapped during execution */
	WASP_ERR_BAD_ARGS = 0x0A,    /* malformed CALL payload or signature mismatch */
	WASP_ERR_NO_FUNC = 0x0B,     /* export not found in loaded module */
	WASP_ERR_LOCKED = 0x0C,      /* region lock held by someone else */
	WASP_ERR_NO_REGION = 0x0D,   /* remote reference names no exported region */
	WASP_ERR_BAD_HANDLE = 0x0E,  /* module/instance handle unknown or retired */
	WASP_ERR_NO_SLOTS = 0x0F,    /* table full, or the pool cannot fit another */
};

/*
 * Return codes of the wasp.* host functions as seen from inside a
 * module. Part of the module ABI — keep in sync with
 * tools/include/wasp/remote.h. Protocol failures (timeout, dropped
 * connection) are not represented here: they raise a WASM exception
 * and surface to the coordinator as ERROR(TRAP).
 */
#define WASP_REMOTE_OK 0
#define WASP_REMOTE_ELOCKED (-1)   /* region locked by someone else */
#define WASP_REMOTE_EBOUNDS (-2)   /* access outside the region */
#define WASP_REMOTE_ENOREGION (-3) /* no such exported region */
#define WASP_REMOTE_EIO (-4)       /* coordinator refused for another reason */

/* v1 calling convention limits (i32 cells only). */
#define WASP_CALL_MAX_ARGS 8
#define WASP_CALL_MAX_RESULTS 4
#define WASP_CALL_MAX_NAME_LEN 63

#endif /* WASP_PROTOCOL_H_ */
```
